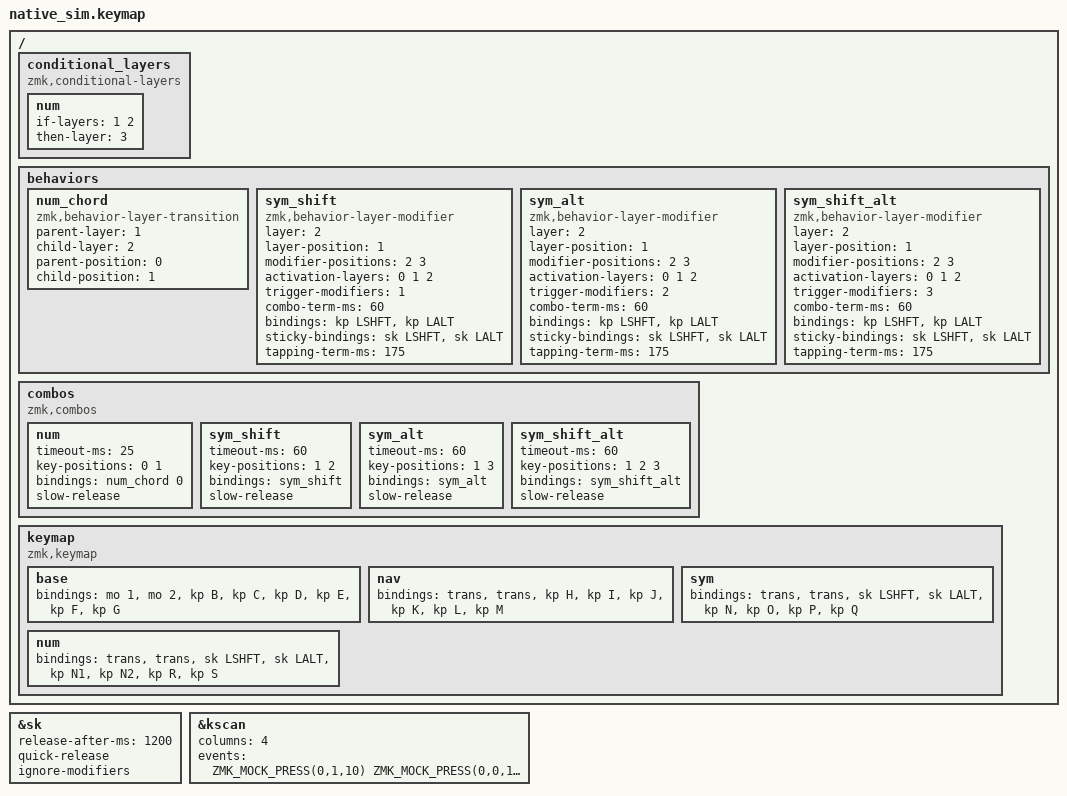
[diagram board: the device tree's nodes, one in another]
#include <behaviors.dtsi>
#include <dt-bindings/zmk/keys.h>
#include <dt-bindings/zmk/kscan_mock.h>

/ {
    conditional_layers {
        compatible = "zmk,conditional-layers";
        num { if-layers = <1 2>; then-layer = <3>; };
    };

    behaviors {
        num_chord: num_chord {
            compatible = "zmk,behavior-layer-transition";
            #binding-cells = <1>;
            parent-layer = <1>;
            child-layer = <2>;
            parent-position = <0>;
            child-position = <1>;
        };
        sym_shift: sym_shift {
            compatible = "zmk,behavior-layer-modifier";
            #binding-cells = <0>;
            layer = <2>;
            layer-position = <1>;
            modifier-positions = <2 3>;
            activation-layers = <0 1 2>;
            trigger-modifiers = <1>;
            combo-term-ms = <60>;
            bindings = <&kp LSHFT>, <&kp LALT>;
            sticky-bindings = <&sk LSHFT>, <&sk LALT>;
            tapping-term-ms = <175>;
        };
        sym_alt: sym_alt {
            compatible = "zmk,behavior-layer-modifier";
            #binding-cells = <0>;
            layer = <2>;
            layer-position = <1>;
            modifier-positions = <2 3>;
            activation-layers = <0 1 2>;
            trigger-modifiers = <2>;
            combo-term-ms = <60>;
            bindings = <&kp LSHFT>, <&kp LALT>;
            sticky-bindings = <&sk LSHFT>, <&sk LALT>;
            tapping-term-ms = <175>;
        };
        sym_shift_alt: sym_shift_alt {
            compatible = "zmk,behavior-layer-modifier";
            #binding-cells = <0>;
            layer = <2>;
            layer-position = <1>;
            modifier-positions = <2 3>;
            activation-layers = <0 1 2>;
            trigger-modifiers = <3>;
            combo-term-ms = <60>;
            bindings = <&kp LSHFT>, <&kp LALT>;
            sticky-bindings = <&sk LSHFT>, <&sk LALT>;
            tapping-term-ms = <175>;
        };
    };

    combos {
        compatible = "zmk,combos";
        num { timeout-ms = <25>; key-positions = <0 1>; bindings = <&num_chord 0>; slow-release; };
        sym_shift { timeout-ms = <60>; key-positions = <1 2>; bindings = <&sym_shift>; slow-release; };
        sym_alt { timeout-ms = <60>; key-positions = <1 3>; bindings = <&sym_alt>; slow-release; };
        sym_shift_alt { timeout-ms = <60>; key-positions = <1 2 3>; bindings = <&sym_shift_alt>; slow-release; };
    };

    keymap {
        compatible = "zmk,keymap";
        base { bindings = <&mo 1 &mo 2 &kp B &kp C &kp D &kp E &kp F &kp G>; };
        nav { bindings = <&trans &trans &kp H &kp I &kp J &kp K &kp L &kp M>; };
        sym { bindings = <&trans &trans &sk LSHFT &sk LALT &kp N &kp O &kp P &kp Q>; };
        num { bindings = <&trans &trans &sk LSHFT &sk LALT &kp N1 &kp N2 &kp R &kp S>; };
    };
};

&sk { release-after-ms = <1200>; quick-release; ignore-modifiers; };

&kscan {
    columns = <4>;
    events = <
        ZMK_MOCK_PRESS(0,1,10)
        ZMK_MOCK_PRESS(0,0,10)
        ZMK_MOCK_PRESS(0,2,10)
        ZMK_MOCK_PRESS(0,3,10)
        ZMK_MOCK_RELEASE(0,3,10)
        ZMK_MOCK_RELEASE(0,2,10)
        ZMK_MOCK_PRESS(1,0,10)
        ZMK_MOCK_RELEASE(1,0,10)
        ZMK_MOCK_PRESS(0,2,10)
        ZMK_MOCK_PRESS(0,3,10)
        ZMK_MOCK_RELEASE(0,3,10)
        ZMK_MOCK_RELEASE(0,2,10)
        ZMK_MOCK_PRESS(1,1,10)
        ZMK_MOCK_RELEASE(1,1,10)
        ZMK_MOCK_RELEASE(0,0,10)
        ZMK_MOCK_RELEASE(0,1,10)
        ZMK_MOCK_PRESS(1,2,10)
        ZMK_MOCK_RELEASE(1,2,10)

        ZMK_MOCK_PRESS(0,2,10)
        ZMK_MOCK_PRESS(0,3,10)
        ZMK_MOCK_PRESS(0,1,10)
        ZMK_MOCK_PRESS(0,0,10)
        ZMK_MOCK_RELEASE(0,3,10)
        ZMK_MOCK_RELEASE(0,2,10)
        ZMK_MOCK_PRESS(1,0,10)
        ZMK_MOCK_RELEASE(1,0,10)
        ZMK_MOCK_RELEASE(0,0,10)
        ZMK_MOCK_RELEASE(0,1,10)
        ZMK_MOCK_PRESS(1,2,10)
        ZMK_MOCK_RELEASE(1,2,10)

        ZMK_MOCK_PRESS(0,1,10)
        ZMK_MOCK_PRESS(0,3,10)
        ZMK_MOCK_RELEASE(0,1,10)
        ZMK_MOCK_PRESS(0,2,10)
        ZMK_MOCK_RELEASE(0,2,10)
        ZMK_MOCK_RELEASE(0,3,10)
        ZMK_MOCK_PRESS(0,2,10)
        ZMK_MOCK_RELEASE(0,2,10)
        ZMK_MOCK_PRESS(0,3,10)
        ZMK_MOCK_RELEASE(0,3,10)
    >;
};
